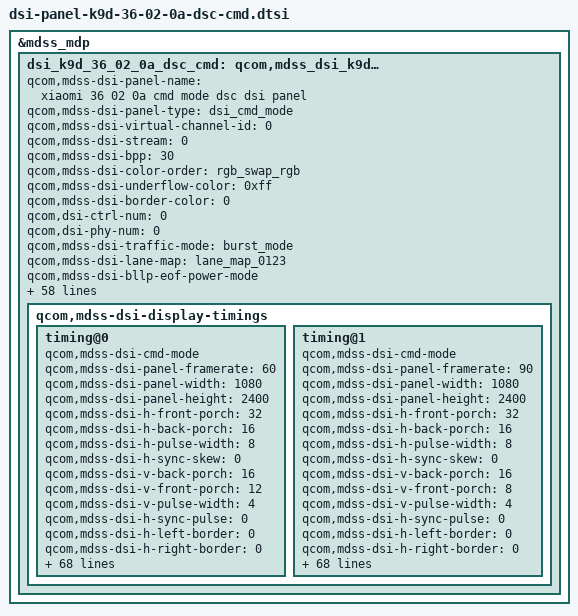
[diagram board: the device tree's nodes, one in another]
// Written by Divyanshu-Modi <Atom-X-Devs https://github.com/Atom-X-Devs>

&mdss_mdp {
	dsi_k9d_36_02_0a_dsc_cmd: qcom,mdss_dsi_k9d_36_02_0a_dsc_cmd {
		qcom,mdss-dsi-panel-name = "xiaomi 36 02 0a cmd mode dsc dsi panel";
		qcom,mdss-dsi-panel-type = "dsi_cmd_mode";
		qcom,mdss-dsi-virtual-channel-id = <0>;
		qcom,mdss-dsi-stream = <0>;
		qcom,mdss-dsi-bpp = <30>;
		qcom,mdss-dsi-color-order = "rgb_swap_rgb";
		qcom,mdss-dsi-underflow-color = <0xff>;
		qcom,mdss-dsi-border-color = <0>;

		qcom,dsi-ctrl-num = <0>;
		qcom,dsi-phy-num = <0>;

		qcom,mdss-dsi-traffic-mode = "burst_mode";
		qcom,mdss-dsi-lane-map = "lane_map_0123";
		qcom,mdss-dsi-bllp-eof-power-mode;
		qcom,mdss-dsi-bllp-power-mode;
		qcom,mdss-dsi-lane-0-state;
		qcom,mdss-dsi-lane-1-state;
		qcom,mdss-dsi-lane-2-state;
		qcom,mdss-dsi-lane-3-state;
		qcom,mdss-dsi-dma-trigger = "trigger_sw";
		qcom,mdss-dsi-mdp-trigger = "none";
		qcom,mdss-dsi-reset-sequence = <1 11>, <0 1>, <1 11>;
		qcom,mdss-pan-physical-width-dimension = <68>;
		qcom,mdss-pan-physical-height-dimension = <152>;
		qcom,mdss-dsi-te-pin-select = <1>;
		qcom,mdss-dsi-wr-mem-start = <0x2c>;
		qcom,mdss-dsi-wr-mem-continue = <0x3c>;
		qcom,mdss-dsi-te-dcs-command = <1>;
		qcom,mdss-dsi-te-check-enable;
		qcom,mdss-dsi-te-using-te-pin;
		qcom,mdss-dsi-tx-eot-append;
		qcom,mdss-dsi-lp11-init;

		qcom,mdss-dsi-bl-inverted-dbv;
		qcom,bl-update-flag = "delay_until_first_frame";

		qcom,mdss-dsi-panel-hdr-enabled;
		qcom,mdss-dsi-panel-hdr-color-primaries = <14500 15500 32000 17000 15500 30000 8000 3000>;
		qcom,mdss-dsi-panel-peak-brightness = <4200000>;
		qcom,mdss-dsi-panel-blackness-level = <3230>;

		qcom,esd-check-enabled;
		qcom,esd-aod-check-enabled;
		qcom,mdss-dsi-panel-status-check-mode = "reg_read";
		qcom,mdss-dsi-panel-status-offset-command = [
			39 01 00 00 00 00 05 ff aa 55 a5 
			81 15 01 00 00 00 00 02 6f 0f
		];
		qcom,mdss-dsi-panel-status-command = <0x6010000 0x1fa>;
		qcom,mdss-dsi-panel-status-command-state = "dsi_lp_mode";
		qcom,mdss-dsi-panel-status-offset-command-state = "dsi_lp_mode";
		qcom,mdss-dsi-panel-status-value = <0>;
		qcom,mdss-dsi-panel-status-read-length = <1>;
		qcom,mdss-dsi-clk-strength = <0xff>;
		qcom,mdss-dsi-dma-schedule-line = <1>;
		qcom,mdss-dsi-dma-schedule-window = <50>;

		qcom,mdss-dsi-factory-bl-max-level = <2047>;
		qcom,mdss-factory-brightness-max-level = <2047>;

		qcom,mdss-dsi-display-timings {
			timing@0 {
				qcom,mdss-dsi-cmd-mode;
				qcom,mdss-dsi-panel-framerate = <60>;
				qcom,mdss-dsi-panel-width = <1080>;
				qcom,mdss-dsi-panel-height = <2400>;
				qcom,mdss-dsi-h-front-porch = <32>;
				qcom,mdss-dsi-h-back-porch = <16>;
				qcom,mdss-dsi-h-pulse-width = <8>;
				qcom,mdss-dsi-h-sync-skew = <0>;
				qcom,mdss-dsi-v-back-porch = <16>;
				qcom,mdss-dsi-v-front-porch = <12>;
				qcom,mdss-dsi-v-pulse-width = <4>;
				qcom,mdss-dsi-h-sync-pulse = <0>;
				qcom,mdss-dsi-h-left-border = <0>;
				qcom,mdss-dsi-h-right-border = <0>;
				qcom,mdss-dsi-v-top-border = <0>;
				qcom,mdss-dsi-v-bottom-border = <0>;
				qcom,mdss-dsi-panel-clockrate = <682000000>;
				qcom,mdss-dsi-panel-jitter = <0x05 0x01>;
				qcom,mdss-mdp-transfer-time-us = <15700>;
				qcom,mdss-dsi-on-command = [
					39 01 00 00 00 00 06 f0 55 aa 52 08 00 39 00 00 00 00 00 09 ba 01 e6 00 10 00 30 00 01 15 00 00 00 00 00 02 b2 58 15 00 00 00 00 00 02 6f 02 39 00 00 00 00 00 03 b2 0c 0c 39 00 00 00 00 00 05 be 0e 0b 14 13 15 00 00 00 00 00 02 6f 05 15 00 00 00 00 00 02 be 8a 15 00 00 00 00 00 02 c0 66 15 00 00 00 00 00 02 6f 08 15 01 00 00 00 00 02 b5 32 39 00 00 00 00 00 06 f0 55 aa 52 08 07 39 01 00 00 00 00 02 c0 01 39 00 00 00 00 00 2c c1 30 0f 04 c9 0f 81 ee c6 3f fb b3 6a 3f f6 d1 42 80 00 f7 33 b1 00 18 00 00 8b 23 33 c0 0f b9 0f dd 8d 00 00 00 0d 08 00 17 23 00 39 00 00 00 00 00 2c c2 38 0f 0b 64 02 11 f6 4c 3f fa e2 14 ff fe 41 a8 00 00 5e 26 90 00 00 24 00 17 90 33 c0 09 b4 0f 94 e9 00 00 90 0d 3c 90 17 57 00 39 00 00 00 00 00 2c c3 3c 00 04 c9 0f 81 11 3a 3f f9 58 7c 00 04 f1 78 00 00 00 00 00 90 18 3c 90 8b 5f 33 60 00 00 0c dd 73 00 00 04 20 08 04 2a 23 00 39 01 00 00 00 00 2c c4 3c 00 0b 64 02 11 09 b4 3f f6 ca 24 c0 00 00 00 00 00 00 00 00 80 00 cf 90 17 3b 33 c0 00 00 0c 94 17 00 00 94 20 3c 94 2a 57 00 39 00 00 00 00 00 2c c5 26 00 04 c9 0f 81 11 3a 00 00 00 00 3f ef 14 34 80 00 00 00 00 03 ac 00 04 1f 23 33 c0 00 00 03 23 8d 00 00 00 00 00 00 00 00 00 39 00 00 00 00 00 2c c6 2e 00 0b 64 02 11 09 b4 00 03 11 f4 ff fd 62 7c 00 00 00 00 00 04 20 24 04 37 90 33 c0 00 00 03 6c e9 00 00 00 00 00 00 00 00 00 39 00 00 00 00 00 2c c7 2a 0f 04 c9 0f 81 ee c6 00 02 5a ee 00 0c ae 86 7f fd f9 f3 65 93 ac 3c 94 1f 5f 33 6f f0 47 00 23 73 00 00 00 00 00 00 00 00 00 39 01 00 00 00 00 2c c8 2a 0f 0b 64 02 11 f6 4c 00 07 29 e4 c0 00 df 2c 7f ff 43 b2 e0 84 20 cf 94 37 3b 33 cf f6 4c 00 6c 17 00 00 00 00 00 00 00 00 00 39 00 00 00 00 00 2c c9 27 00 03 c1 04 41 00 00 00 00 00 00 3f fe f8 42 00 00 00 00 00 00 63 24 00 84 43 33 90 00 00 03 1f df 00 00 00 00 00 00 00 00 00 39 00 00 00 00 00 2c ca 21 00 03 c1 04 00 00 00 3f ff 0f c0 3f ff 08 00 00 00 0f 04 00 00 42 24 00 62 43 33 90 03 e0 0f e1 e0 00 00 00 00 00 00 00 00 00 39 00 00 00 00 00 2c cb 2d 00 04 00 04 00 00 00 3f ff 00 00 00 00 00 00 80 00 00 00 00 00 42 44 00 62 64 33 60 00 00 0c e0 20 00 00 00 00 00 00 00 00 00 39 01 00 00 00 00 2c cc 2b 00 04 00 04 41 00 00 00 00 00 00 00 00 00 00 ff ff ee fc 00 00 63 44 00 84 64 33 6f fb e0 00 20 21 00 00 00 00 00 00 00 00 00 15 00 00 00 00 00 02 b4 c0 15 00 00 00 00 00 02 6f 01 39 01 00 00 00 00 04 b4 00 80 80 39 01 00 00 00 00 06 f0 55 aa 52 08 01 39 00 00 00 00 00 02 6f 01 39 00 00 00 00 00 04 d2 00 00 11 39 00 00 00 00 00 02 6f 06 39 00 00 00 00 00 02 d2 05 39 00 00 00 00 00 02 6f 0f 39 00 00 00 00 00 02 d2 00 39 00 00 00 00 00 02 6f 09 39 00 00 00 00 00 03 d2 00 00 39 00 00 00 00 00 02 ce 00 39 00 00 00 00 00 05 ff aa 55 a5 80 39 00 00 00 00 00 02 6f 61 39 00 00 00 00 00 02 f3 80 39 00 00 00 00 00 06 f0 55 aa 52 08 00 39 00 00 00 00 00 02 c0 46 39 00 00 00 00 00 03 be 0e 0b 39 00 00 00 00 00 02 6f 05 39 00 00 00 00 00 02 be 88 39 00 00 00 00 00 02 6f 08 39 00 00 00 00 00 02 b5 32 39 00 00 00 00 00 02 6f 0b 39 00 00 00 00 00 04 b5 33 23 2b 39 00 00 00 00 00 06 f0 55 aa 52 08 01 39 00 00 00 00 00 04 d1 07 00 04 39 00 00 00 00 00 05 3b 00 10 00 30 39 00 00 00 00 00 02 d9 c8 15 01 00 00 00 00 02 90 01 39 00 00 00 00 00 13 91 ab 28 00 0c c2 00 03 1c 01 7e 00 0f 08 bb 04 3d 10 f0 15 00 00 00 00 00 02 03 01 39 00 00 00 00 00 05 51 00 00 00 00 15 00 00 00 00 00 02 53 20 15 00 00 00 00 00 02 35 00 39 00 00 00 00 00 05 2a 00 00 04 37 39 00 00 00 00 00 05 2b 00 00 09 5f 15 01 00 00 00 00 02 2f 02 39 00 00 00 00 00 05 ff aa 55 a5 81 15 00 00 00 00 00 02 6f 0f 39 00 00 00 00 00 03 fd 01 5a 15 00 00 00 00 00 02 6f 04 15 00 00 00 00 00 02 fd 5f 15 00 00 00 00 00 02 6f 1a 15 00 00 00 00 00 02 fd 5f 05 01 00 00 00 00 01 2c 39 00 00 00 00 00 06 f0 55 aa 52 08 00 39 00 00 00 00 00 05 ca 12 00 92 02 15 00 00 00 00 00 02 6f 02 39 00 00 00 00 00 03 ec 80 10 39 00 00 00 00 00 06 f0 55 aa 52 08 01 39 00 00 00 00 00 03 cd 05 31 15 00 00 00 00 00 02 6f 10 15 00 00 00 00 00 02 d8 0c 39 00 00 00 00 00 06 f0 55 aa 52 08 05 39 00 00 00 00 00 03 b3 86 80 39 00 00 00 00 00 03 b5 85 81 39 00 00 00 00 00 05 b7 85 00 00 81 39 00 00 00 00 00 05 b8 05 00 00 81 39 00 00 00 00 00 03 ec 0d 11 15 00 00 00 00 00 02 6f 02 39 01 00 00 00 00 13 ec 00 00 00 00 00 00 00 00 00 00 00 00 00 00 00 00 00 00 39 01 00 00 00 00 06 f0 55 aa 52 08 00 39 01 00 00 00 00 02 6f 08 39 01 00 00 00 00 02 b5 32 39 01 00 00 00 00 02 6f 0b 39 01 00 00 00 00 04 b5 33 23 2b 39 01 00 00 00 00 06 f0 55 aa 52 08 01 39 01 00 00 00 00 02 ce 00 39 00 00 00 00 00 06 f0 55 aa 52 08 01 39 00 00 00 00 00 08 c3 94 01 97 d0 22 02 00 05 01 00 00 10 00 02 11 00 05 01 00 00 00 00 02 29 00
				];
				qcom,mdss-dsi-off-command = [
					05 01 00 00 14 00 02 28 00 
					05 01 00 00 50 00 02 10 00
				];
				qcom,mdss-dsi-on-command-state = "dsi_lp_mode";
				qcom,mdss-dsi-off-command-state = "dsi_lp_mode";
				qcom,mdss-dsi-timing-switch-command = [
					15 01 00 00 00 00 02 2f 02
				];
				qcom,mdss-dsi-timing-switch-command-state = "dsi_lp_mode";
				qcom,mdss-dsi-nolp-command = [
					15 01 00 00 00 00 02 65 00 
					05 01 00 00 07 00 01 38 39 
					01 00 00 00 00 06 f0 55 aa 
					52 08 01 39 01 00 00 1b 00 
					05 ba 10 1a 10 1a 39 01 00 
					00 00 00 05 ba 10 10 10 10 
					15 01 00 00 00 00 02 2f 02
				];
				qcom,mdss-dsi-nolp-command-state = "dsi_lp_mode";
				qcom,compression-mode = "dsc";
				qcom,mdss-dsc-version = <0x11>;
				qcom,mdss-dsc-scr-version = <0>;
				qcom,mdss-dsc-slice-height = <12>;
				qcom,mdss-dsc-slice-width = <1080>;
				qcom,mdss-dsc-slice-per-pkt = <2>;
				qcom,mdss-dsc-bit-per-component = <10>;
				qcom,mdss-dsc-bit-per-pixel = <8>;
				qcom,mdss-dsc-block-prediction-enable;
			};

			timing@1 {
				qcom,mdss-dsi-cmd-mode;
				qcom,mdss-dsi-panel-framerate = <90>;
				qcom,mdss-dsi-panel-width = <1080>;
				qcom,mdss-dsi-panel-height = <2400>;
				qcom,mdss-dsi-h-front-porch = <32>;
				qcom,mdss-dsi-h-back-porch = <16>;
				qcom,mdss-dsi-h-pulse-width = <8>;
				qcom,mdss-dsi-h-sync-skew = <0>;
				qcom,mdss-dsi-v-back-porch = <16>;
				qcom,mdss-dsi-v-front-porch = <8>;
				qcom,mdss-dsi-v-pulse-width = <4>;
				qcom,mdss-dsi-h-sync-pulse = <0>;
				qcom,mdss-dsi-h-left-border = <0>;
				qcom,mdss-dsi-h-right-border = <0>;
				qcom,mdss-dsi-v-top-border = <0>;
				qcom,mdss-dsi-v-bottom-border = <0>;
				qcom,mdss-dsi-panel-clockrate = <682000000>;
				qcom,mdss-dsi-panel-jitter = <0x05 0x01>;
				qcom,mdss-mdp-transfer-time-us = <9500>;
				qcom,mdss-dsi-on-command = [
					39 01 00 00 00 00 06 f0 55 aa 52 08 00 39 00 00 00 00 00 09 ba 01 e6 00 10 00 30 00 01 15 00 00 00 00 00 02 b2 58 15 00 00 00 00 00 02 6f 02 39 00 00 00 00 00 03 b2 12 12 39 00 00 00 00 00 05 be 0e 0b 14 13 15 00 00 00 00 00 02 6f 05 15 00 00 00 00 00 02 be 8a 15 00 00 00 00 00 02 c0 66 15 00 00 00 00 00 02 6f 08 15 00 00 00 00 00 02 b5 32 39 00 00 00 00 00 06 f0 55 aa 52 08 07 39 01 00 00 00 00 02 c0 01 39 00 00 00 00 00 2c c1 30 0f 04 c9 0f 81 ee c6 3f fb b3 6a 3f f6 d1 42 80 00 f7 33 b1 00 18 00 00 8b 23 33 c0 0f b9 0f dd 8d 00 00 00 0d 08 00 17 23 00 39 00 00 00 00 00 2c c2 38 0f 0b 64 02 11 f6 4c 3f fa e2 14 ff fe 41 a8 00 00 5e 26 90 00 00 24 00 17 90 33 c0 09 b4 0f 94 e9 00 00 90 0d 3c 90 17 57 00 39 00 00 00 00 00 2c c3 3c 00 04 c9 0f 81 11 3a 3f f9 58 7c 00 04 f1 78 00 00 00 00 00 90 18 3c 90 8b 5f 33 60 00 00 0c dd 73 00 00 04 20 08 04 2a 23 00 39 01 00 00 00 00 2c c4 3c 00 0b 64 02 11 09 b4 3f f6 ca 24 c0 00 00 00 00 00 00 00 00 80 00 cf 90 17 3b 33 c0 00 00 0c 94 17 00 00 94 20 3c 94 2a 57 00 39 00 00 00 00 00 2c c5 26 00 04 c9 0f 81 11 3a 00 00 00 00 3f ef 14 34 80 00 00 00 00 03 ac 00 04 1f 23 33 c0 00 00 03 23 8d 00 00 00 00 00 00 00 00 00 39 00 00 00 00 00 2c c6 2e 00 0b 64 02 11 09 b4 00 03 11 f4 ff fd 62 7c 00 00 00 00 00 04 20 24 04 37 90 33 c0 00 00 03 6c e9 00 00 00 00 00 00 00 00 00 39 00 00 00 00 00 2c c7 2a 0f 04 c9 0f 81 ee c6 00 02 5a ee 00 0c ae 86 7f fd f9 f3 65 93 ac 3c 94 1f 5f 33 6f f0 47 00 23 73 00 00 00 00 00 00 00 00 00 39 01 00 00 00 00 2c c8 2a 0f 0b 64 02 11 f6 4c 00 07 29 e4 c0 00 df 2c 7f ff 43 b2 e0 84 20 cf 94 37 3b 33 cf f6 4c 00 6c 17 00 00 00 00 00 00 00 00 00 39 00 00 00 00 00 2c c9 27 00 03 c1 04 41 00 00 00 00 00 00 3f fe f8 42 00 00 00 00 00 00 63 24 00 84 43 33 90 00 00 03 1f df 00 00 00 00 00 00 00 00 00 39 00 00 00 00 00 2c ca 21 00 03 c1 04 00 00 00 3f ff 0f c0 3f ff 08 00 00 00 0f 04 00 00 42 24 00 62 43 33 90 03 e0 0f e1 e0 00 00 00 00 00 00 00 00 00 39 00 00 00 00 00 2c cb 2d 00 04 00 04 00 00 00 3f ff 00 00 00 00 00 00 80 00 00 00 00 00 42 44 00 62 64 33 60 00 00 0c e0 20 00 00 00 00 00 00 00 00 00 39 01 00 00 00 00 2c cc 2b 00 04 00 04 41 00 00 00 00 00 00 00 00 00 00 ff ff ee fc 00 00 63 44 00 84 64 33 6f fb e0 00 20 21 00 00 00 00 00 00 00 00 00 15 00 00 00 00 00 02 b4 c0 15 00 00 00 00 00 02 6f 01 39 01 00 00 00 00 04 b4 00 80 80 39 01 00 00 00 00 06 f0 55 aa 52 08 01 39 00 00 00 00 00 02 6f 01 39 00 00 00 00 00 04 d2 00 00 11 39 00 00 00 00 00 02 6f 06 39 00 00 00 00 00 02 d2 05 39 00 00 00 00 00 02 6f 0f 39 00 00 00 00 00 02 d2 00 39 00 00 00 00 00 02 6f 09 39 00 00 00 00 00 03 d2 00 00 39 00 00 00 00 00 02 ce 00 39 00 00 00 00 00 05 ff aa 55 a5 80 39 00 00 00 00 00 02 6f 61 39 00 00 00 00 00 02 f3 80 39 00 00 00 00 00 06 f0 55 aa 52 08 00 39 00 00 00 00 00 02 c0 46 39 00 00 00 00 00 03 be 0e 0b 39 00 00 00 00 00 02 6f 05 39 00 00 00 00 00 02 be 88 39 00 00 00 00 00 02 6f 08 39 00 00 00 00 00 02 b5 32 39 00 00 00 00 00 02 6f 0b 39 00 00 00 00 00 04 b5 33 23 2b 39 00 00 00 00 00 06 f0 55 aa 52 08 01 39 00 00 00 00 00 04 d1 07 00 04 39 00 00 00 00 00 05 3b 00 10 00 30 39 00 00 00 00 00 02 d9 c8 15 01 00 00 00 00 02 90 01 39 00 00 00 00 00 13 91 ab 28 00 0c c2 00 03 1c 01 7e 00 0f 08 bb 04 3d 10 f0 15 00 00 00 00 00 02 03 01 39 00 00 00 00 00 05 51 00 00 00 00 15 00 00 00 00 00 02 53 20 15 00 00 00 00 00 02 35 00 39 00 00 00 00 00 05 2a 00 00 04 37 39 00 00 00 00 00 05 2b 00 00 09 5f 15 01 00 00 00 00 02 2f 01 39 00 00 00 00 00 05 ff aa 55 a5 81 15 00 00 00 00 00 02 6f 0f 39 00 00 00 00 00 03 fd 01 5a 15 00 00 00 00 00 02 6f 04 15 00 00 00 00 00 02 fd 5f 15 00 00 00 00 00 02 6f 1a 15 00 00 00 00 00 02 fd 5f 05 01 00 00 00 00 01 2c 39 00 00 00 00 00 06 f0 55 aa 52 08 00 39 00 00 00 00 00 05 ca 12 00 92 02 15 00 00 00 00 00 02 6f 02 39 00 00 00 00 00 03 ec 80 10 39 00 00 00 00 00 06 f0 55 aa 52 08 01 39 00 00 00 00 00 03 cd 05 31 15 00 00 00 00 00 02 6f 10 15 00 00 00 00 00 02 d8 0c 39 00 00 00 00 00 06 f0 55 aa 52 08 05 39 00 00 00 00 00 03 b3 86 80 39 00 00 00 00 00 03 b5 85 81 39 00 00 00 00 00 05 b7 85 00 00 81 39 00 00 00 00 00 05 b8 05 00 00 81 39 00 00 00 00 00 03 ec 0d 11 15 00 00 00 00 00 02 6f 02 39 01 00 00 00 00 13 ec 00 00 00 00 00 00 00 00 00 00 00 00 00 00 00 00 00 00 39 01 00 00 00 00 06 f0 55 aa 52 08 00 39 01 00 00 00 00 02 6f 08 39 01 00 00 00 00 02 b5 32 39 01 00 00 00 00 02 6f 0b 39 01 00 00 00 00 04 b5 33 23 2b 39 01 00 00 00 00 06 f0 55 aa 52 08 01 39 01 00 00 00 00 02 ce 00 39 00 00 00 00 00 06 f0 55 aa 52 08 01 39 00 00 00 00 00 08 c3 94 01 97 d0 22 02 00 05 01 00 00 10 00 02 11 00 05 01 00 00 00 00 02 29 00
				];
				qcom,mdss-dsi-off-command = [
					05 01 00 00 14 00 02 28 00 
					05 01 00 00 50 00 02 10 00
				];
				qcom,mdss-dsi-on-command-state = "dsi_lp_mode";
				qcom,mdss-dsi-off-command-state = "dsi_lp_mode";
				qcom,mdss-dsi-timing-switch-command = [
					15 01 00 00 00 00 02 2f 01
				];
				qcom,mdss-dsi-timing-switch-command-state = "dsi_lp_mode";
				qcom,mdss-dsi-nolp-command = [
					15 01 00 00 00 00 02 65 00 
					05 01 00 00 07 00 01 38 39 
					00 00 00 00 00 06 f0 55 aa 
					52 08 01 39 01 00 00 1b 00 
					05 ba 10 1a 10 1a 39 01 00 
					00 00 00 05 ba 10 10 10 10 
					15 01 00 00 00 00 02 2f 01
				];
				qcom,mdss-dsi-nolp-command-state = "dsi_lp_mode";
				qcom,compression-mode = "dsc";
				qcom,mdss-dsc-version = <0x11>;
				qcom,mdss-dsc-scr-version = <0>;
				qcom,mdss-dsc-slice-height = <12>;
				qcom,mdss-dsc-slice-width = <1080>;
				qcom,mdss-dsc-slice-per-pkt = <2>;
				qcom,mdss-dsc-bit-per-component = <10>;
				qcom,mdss-dsc-bit-per-pixel = <8>;
				qcom,mdss-dsc-block-prediction-enable;
			};
		};
	};
};

&dsi_k9d_36_02_0a_dsc_cmd {
	mi,panel-id = <0x4b3944 0x360200>;
	mi,hbm-51-ctl-flag;
	mi,hbm-off-51-index = <1>;
	mi,hbm-on-51-index = <1>;
	mi,hbm-bl-min-level = <1>;
	mi,hbm-bl-max-level = <2047>;
	mi,panel-on-dimming-delay = <120>;
	mi,max-brightness-clone = <4095>;
	mi,mdss-dsi-panel-dc-type = <0>;
	mi,fp-display-on-optimize-flag;
	mi,thermal-dimming-flag;
	mi,timming-switch-wait-for-te-flag;
	mi,esd-err-irq-gpio = <&tlmm 3 0x2002>;
	mi,panel-aod-to-off-command-need-enabled;

	qcom,mdss-dsi-display-timings {
		timing@0 {
			mi,mdss-dsc-panel-id = <0x4b3944 0x360200>;
			mi,mdss-dsi-dimmingon-command = [
				15 01 00 00 00 00 02 53 28
			];
			mi,mdss-dsi-dimmingon-command-state = "dsi_hs_mode";
			mi,mdss-dsi-dimmingoff-command = [
				15 01 00 00 00 00 02 53 20
			];
			mi,mdss-dsi-dimmingoff-command-state = "dsi_hs_mode";
			mi,mdss-dsi-hbm-on-command = [
				15 01 00 00 00 00 02 53 28 
				39 01 00 00 00 00 05 51 0f 
				ff 00 00
			];
			mi,mdss-dsi-hbm-off-command = [
				15 01 00 00 00 00 02 53 28 
				39 01 00 00 00 00 05 51 07 
				ff 00 00
			];
			mi,mdss-dsi-hbm-on-command-state = "dsi_lp_mode";
			mi,mdss-dsi-hbm-off-command-state = "dsi_lp_mode";
			mi,mdss-dsi-doze-hbm-command = [
				15 01 00 00 00 00 02 2F 01
				15 01 00 00 00 00 02 6F 02
				39 01 00 00 00 00 03 51 03
				FF 05 01 00 00 14 00 01 39
				15 01 00 00 00 00 02 65 01
			];
			mi,mdss-dsi-doze-lbm-command = [
				15 01 00 00 00 00 02 2F 01
				15 01 00 00 00 00 02 6F 02
				39 01 00 00 00 00 03 51 01
				FF 05 01 00 00 14 00 01 39
				15 01 00 00 00 00 02 65 01
			];
			mi,mdss-dsi-doze-hbm-command-state = "dsi_lp_mode";
			mi,mdss-dsi-doze-lbm-command-state = "dsi_lp_mode";
			mi,mdss-dsi-flat-mode-on-command = [
				39 01 00 00 00 00 06 f0 55 
				aa 52 08 08 15 01 00 00 00 
				00 02 b9 01
			];
			mi,mdss-dsi-flat-mode-off-command = [
				39 01 00 00 00 00 06 f0 55 
				aa 52 08 08 15 01 00 00 00 
				00 02 b9 00
			];
			mi,mdss-dsi-flat-mode-on-command-state = "dsi_lp_mode";
			mi,mdss-dsi-flat-mode-off-command-state = "dsi_lp_mode";
			mi,mdss-dsi-pre-doze-to-off-command = [
				39 00 00 00 00 00 06 f0 55 
				aa 52 08 01 39 01 00 00 00 
				00 02 ce 0c
			];
			mi,mdss-dsi-pre-doze-to-off-command-state = "dsi_lp_mode";
			mi,mdss-dsi-dc-on-command = [
				/* Enter 60Hz DC */
				15 00 00 00 00 00 02 2F 03
				39 00 00 00 00 00 06 F0 55 AA 52 08 00
				15 00 00 00 00 00 02 B2 C0
				15 00 00 00 00 00 02 6F 11
				39 00 00 00 00 00 03 B2 01 C2
				39 00 00 00 00 00 25 B3
					00 00 00 00 00 00 00 00 00 00
					00 00 00 00 00 00 00 00 00 00
					00 00 00 00 00 00 00 00 00 00
					00 00 07 FF 0F FF
				15 00 00 00 00 00 02 6F 30
				39 00 00 00 00 00 27 B4
					00 6A 00 6A 00 6A 00 6A 00 6A
					00 6A 00 6A 00 6A 00 6A 00 6A
					00 6A 00 6A 00 6A 00 6A 00 6A
					00 6A 00 6A 00 6A 00 6A
				15 00 00 00 00 00 02 6F 10
				39 01 00 00 00 00 09 BA 01 F5 00 10 04 B6 00 01];
			mi,mdss-dsi-dc-on-command-state = "dsi_hs_mode";
			mi,mdss-dsi-dc-off-command = [
				/* Exit 60Hz DC */
				15 00 00 00 00 00 02 2F 02
				39 00 00 00 00 00 06 F0 55 AA 52 08 00
				15 00 00 00 00 00 02 B2 58
				15 00 00 00 00 00 02 6F 0F
				39 00 00 00 00 00 03 B2 20 50
				39 00 00 00 00 00 25 B3
					00 08 00 14 00 14 00 29 00 29
					00 6A 00 6A 00 F6 00 F6 01 C2
					01 C2 02 29 02 29 04 CC 04 CC
					07 FF 07 FF 0F FF
				39 01 00 00 00 00 27 B4
					09 A0 09 6E 08 A9 08 A9 08 44
					08 44 06 F8 06 F8 04 3C 04 3C
					00 48 00 48 00 48 00 48 00 48
					00 48 00 48 00 48 00 48];
			mi,mdss-dsi-dc-off-command-state = "dsi_hs_mode";
		};

		timing@1 {
			mi,mdss-dsc-panel-id = <0x4b3944 0x360200>;
			mi,mdss-dsi-dimmingon-command = [
				15 01 00 00 00 00 02 53 28
			];
			mi,mdss-dsi-dimmingon-command-state = "dsi_hs_mode";
			mi,mdss-dsi-dimmingoff-command = [
				15 01 00 00 00 00 02 53 20
			];
			mi,mdss-dsi-dimmingoff-command-state = "dsi_hs_mode";
			mi,mdss-dsi-hbm-on-command = [
				15 01 00 00 00 00 02 53 28 
				39 01 00 00 00 00 05 51 0f 
				ff 00 00
			];
			mi,mdss-dsi-hbm-off-command = [
				15 01 00 00 00 00 02 53 28 
				39 01 00 00 00 00 05 51 07 
				ff 00 00
			];
			mi,mdss-dsi-hbm-on-command-state = "dsi_lp_mode";
			mi,mdss-dsi-hbm-off-command-state = "dsi_lp_mode";
			mi,mdss-dsi-doze-hbm-command = [
				15 01 00 00 00 00 02 2F 01
				15 01 00 00 00 00 02 6F 02
				39 01 00 00 00 00 03 51 03
				FF 05 01 00 00 14 00 01 39
				15 01 00 00 00 00 02 65 01
			];
			mi,mdss-dsi-doze-lbm-command = [
				15 01 00 00 00 00 02 2F 01
				15 01 00 00 00 00 02 6F 02
				39 01 00 00 00 00 03 51 01
				FF 05 01 00 00 14 00 01 39
				15 01 00 00 00 00 02 65 01
			];
			mi,mdss-dsi-doze-hbm-command-state = "dsi_lp_mode";
			mi,mdss-dsi-doze-lbm-command-state = "dsi_lp_mode";
			mi,mdss-dsi-flat-mode-on-command = [
				39 01 00 00 00 00 06 f0 55 
				aa 52 08 08 15 01 00 00 00 
				00 02 b9 01
			];
			mi,mdss-dsi-flat-mode-off-command = [
				39 01 00 00 00 00 06 f0 55 
				aa 52 08 08 15 01 00 00 00 
				00 02 b9 00
			];
			mi,mdss-dsi-flat-mode-on-command-state = "dsi_lp_mode";
			mi,mdss-dsi-flat-mode-off-command-state = "dsi_lp_mode";
			mi,mdss-dsi-pre-doze-to-off-command = [
				39 00 00 00 00 00 06 f0 55 
				aa 52 08 01 39 01 00 00 00 
				00 02 ce 0c
			];
			mi,mdss-dsi-pre-doze-to-off-command-state = "dsi_lp_mode";
			mi,mdss-dsi-dc-on-command = [
				/* Enter 90Hz DC */
				15 00 00 00 00 00 02 2F 01
				39 00 00 00 00 00 06 F0 55 AA 52 08 00
				15 00 00 00 00 00 02 B2 C0
				15 00 00 00 00 00 02 6F 0F
				39 00 00 00 00 00 03 B2 00 50
				39 00 00 00 00 00 25 B3
					00 00 00 00 00 00 00 00 00 00
					00 00 00 00 00 00 00 00 00 00
					00 00 00 00 00 00 00 00 00 00
					00 00 07 FF 0F FF
				39 01 00 00 00 00 27 B4
					00 48 00 48 00 48 00 48 00 48
					00 48 00 48 00 48 00 48 00 48
					00 48 00 48 00 48 00 48 00 48
					00 48 00 48 00 48 00 48];
			mi,mdss-dsi-dc-on-command-state = "dsi_hs_mode";
			mi,mdss-dsi-dc-off-command = [
				/* Exit 90Hz DC */
				15 00 00 00 00 00 02 2F 01
				39 00 00 00 00 00 06 F0 55 AA 52 08 00
				15 00 00 00 00 00 02 B2 58
				15 00 00 00 00 00 02 6F 0F
				39 00 00 00 00 00 03 B2 20 50
				39 00 00 00 00 00 25 B3
					00 08 00 14 00 14 00 29 00 29
					00 6A 00 6A 00 F6 00 F6 01 C2
					01 C2 02 29 02 29 04 CC 04 CC
					07 FF 07 FF 0F FF
				39 01 00 00 00 00 27 B4
					09 A0 09 6E 08 A9 08 A9 08 44
					08 44 06 F8 06 F8 04 3C 04 3C
					00 48 00 48 00 48 00 48 00 48
					00 48 00 48 00 48 00 48];
			mi,mdss-dsi-dc-off-command-state = "dsi_hs_mode";
		};
	};
};
